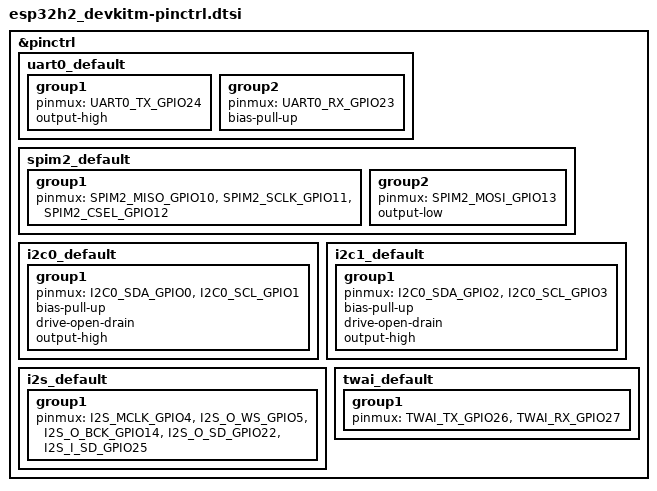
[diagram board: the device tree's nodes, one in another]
/*
 * Copyright (c) 2025 Espressif Systems (Shanghai) Co., Ltd.
 *
 * SPDX-License-Identifier: Apache-2.0
 */

#include <zephyr/dt-bindings/pinctrl/esp-pinctrl-common.h>
#include <dt-bindings/pinctrl/esp32h2-pinctrl.h>
#include <zephyr/dt-bindings/pinctrl/esp32h2-gpio-sigmap.h>

&pinctrl {
	uart0_default: uart0_default {
		group1 {
			pinmux = <UART0_TX_GPIO24>;
			output-high;
		};

		group2 {
			pinmux = <UART0_RX_GPIO23>;
			bias-pull-up;
		};
	};

	spim2_default: spim2_default {
		group1 {
			pinmux = <SPIM2_MISO_GPIO10>,
				 <SPIM2_SCLK_GPIO11>,
				 <SPIM2_CSEL_GPIO12>;
		};

		group2 {
			pinmux = <SPIM2_MOSI_GPIO13>;
			output-low;
		};
	};

	i2c0_default: i2c0_default {
		group1 {
			pinmux = <I2C0_SDA_GPIO0>,
				 <I2C0_SCL_GPIO1>;
			bias-pull-up;
			drive-open-drain;
			output-high;
		};
	};

	i2c1_default: i2c1_default {
		group1 {
			pinmux = <I2C0_SDA_GPIO2>,
				 <I2C0_SCL_GPIO3>;
			bias-pull-up;
			drive-open-drain;
			output-high;
		};
	};

	i2s_default: i2s_default {
		group1 {
			pinmux = <I2S_MCLK_GPIO4>,
				 <I2S_O_WS_GPIO5>,
				 <I2S_O_BCK_GPIO14>,
				 <I2S_O_SD_GPIO22>,
				 <I2S_I_SD_GPIO25>;
		};
	};

	twai_default: twai_default {
		group1 {
			pinmux = <TWAI_TX_GPIO26>,
				 <TWAI_RX_GPIO27>;
		};
	};
};
